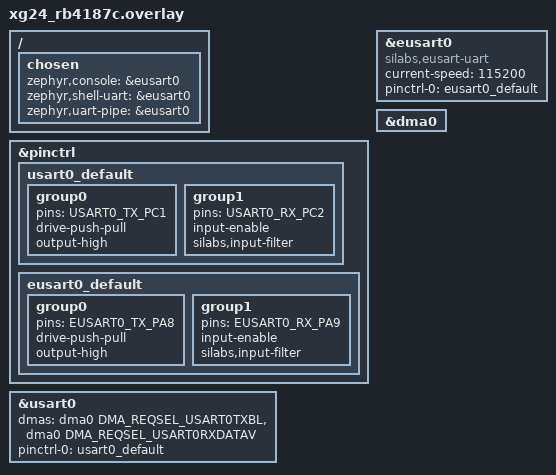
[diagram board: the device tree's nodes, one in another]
/*
 * Copyright (c) 2025, Silicon Laboratories Inc.
 *
 * SPDX-License-Identifier: Apache-2.0
 */

/*
 * Need to connect PC1 and PC2 of the Expension Pin header
 */
/ {
	chosen {
		zephyr,console = &eusart0;
		zephyr,shell-uart = &eusart0;
		zephyr,uart-pipe = &eusart0;
	};
};

&pinctrl{
	usart0_default: usart0_default {
		group0 {
			pins = <USART0_TX_PC1>;
			drive-push-pull;
			output-high;
		};
		group1 {
			pins = <USART0_RX_PC2>;
			input-enable;
			silabs,input-filter;
		};
	};
	eusart0_default: eusart0_default {
		group0 {
			pins = <EUSART0_TX_PA8>;
			drive-push-pull;
			output-high;
		};
		group1 {
			pins = <EUSART0_RX_PA9>;
			input-enable;
			silabs,input-filter;
		};
	};
};

dut: &usart0 {
	dmas = <&dma0 DMA_REQSEL_USART0TXBL>,
	       <&dma0 DMA_REQSEL_USART0RXDATAV>;
	dma-names = "tx", "rx";
	pinctrl-0 = <&usart0_default>;
	pinctrl-names = "default";
};

&eusart0 {
	compatible = "silabs,eusart-uart";
	current-speed = <115200>;
	pinctrl-0 = <&eusart0_default>;
	pinctrl-names = "default";
	status = "okay";
};

&dma0 {
	status = "okay";
};
